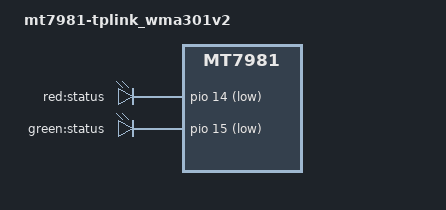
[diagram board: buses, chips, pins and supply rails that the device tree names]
// SPDX-License-Identifier: GPL-2.0-or-later OR MIT

/dts-v1/;
#include "mt7981-tplink-wma301.dtsi"

/ {
	model = "mt7981-tplink_wma301v2";
	compatible = "mediatek,mt7981", "mediatek,mt7981-rfb";

	leds {
		compatible = "gpio-leds";

		status_red_led: led-0 {
			label = "red:status";
			gpios = <&pio 14 GPIO_ACTIVE_LOW>;
		};

		status_green_led: led-1 {
			label = "green:status";
			gpios = <&pio 15 GPIO_ACTIVE_LOW>;
		};
	};
};
